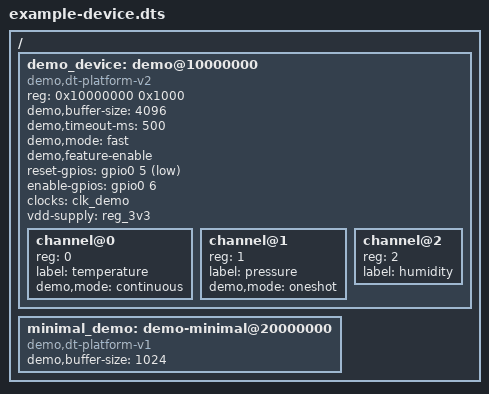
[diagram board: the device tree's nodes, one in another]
/*
 * Example Device Tree Snippet
 *
 * This shows how to add a device node for dt_platform_demo driver.
 * Add this to your board's device tree file or as an overlay.
 */

/* Example: Full device node */
/ {
    demo_device: demo@10000000 {
        compatible = "demo,dt-platform-v2";

        /* Memory region (optional for this demo) */
        reg = <0x10000000 0x1000>;

        /* Custom properties */
        demo,buffer-size = <4096>;      /* Required */
        demo,timeout-ms = <500>;        /* Optional, default 1000 */
        demo,mode = "fast";             /* Optional, default "normal" */
        demo,feature-enable;            /* Boolean, presence = true */

        /* GPIO references (optional) */
        reset-gpios = <&gpio0 5 GPIO_ACTIVE_LOW>;
        enable-gpios = <&gpio0 6 GPIO_ACTIVE_HIGH>;

        /* Clock reference (optional) */
        clocks = <&clk_demo>;
        clock-names = "demo";

        /* Power supply (optional) */
        vdd-supply = <&reg_3v3>;

        /* Child nodes for channels */
        channel@0 {
            reg = <0>;
            label = "temperature";
            demo,mode = "continuous";
        };

        channel@1 {
            reg = <1>;
            label = "pressure";
            demo,mode = "oneshot";
        };

        channel@2 {
            reg = <2>;
            label = "humidity";
            /* Uses default mode */
        };
    };
};

/*
 * Example: Minimal device node (only required properties)
 */
/ {
    minimal_demo: demo-minimal@20000000 {
        compatible = "demo,dt-platform-v1";
        demo,buffer-size = <1024>;
    };
};

/*
 * Example: As a Device Tree Overlay
 *
 * Save as overlay.dts and compile with:
 *   dtc -I dts -O dtb -@ -o overlay.dtbo overlay.dts
 */
/*
/dts-v1/;
/plugin/;

/ {
    fragment@0 {
        target-path = "/";
        __overlay__ {
            demo_device: demo@10000000 {
                compatible = "demo,dt-platform-v2";
                demo,buffer-size = <2048>;
                demo,mode = "low-power";

                channel@0 {
                    reg = <0>;
                    label = "sensor";
                };
            };
        };
    };
};
*/
